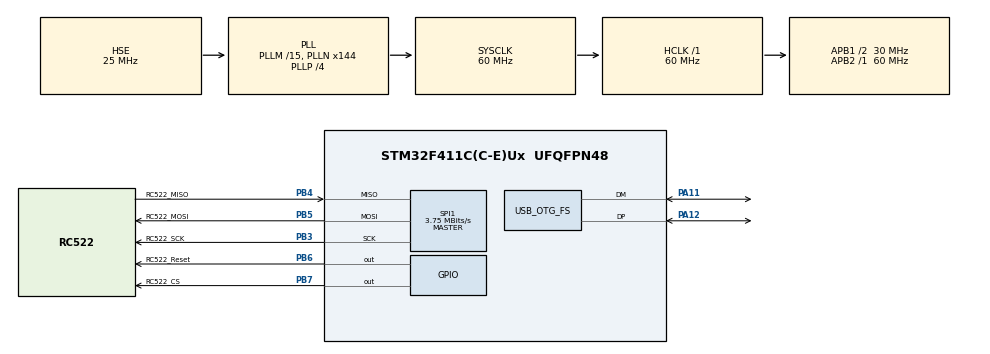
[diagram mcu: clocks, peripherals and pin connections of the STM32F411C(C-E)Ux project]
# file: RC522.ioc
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Mcu.Family=STM32F4
Mcu.Name=STM32F411C(C-E)Ux
Mcu.Package=UFQFPN48
NVIC.OTG_FS_IRQn=true\:0\:0\:false\:false\:true\:false\:true
NVIC.PriorityGroup=NVIC_PRIORITYGROUP_4
PA11.Mode=Device_Only
PA11.Signal=USB_OTG_FS_DM
PA12.Mode=Device_Only
PA12.Signal=USB_OTG_FS_DP
PA13.Mode=Serial_Wire
PA13.Signal=SYS_JTMS-SWDIO
PA14.Mode=Serial_Wire
PA14.Signal=SYS_JTCK-SWCLK
PB3.GPIO_Label=RC522_SCK
PB3.Mode=Full_Duplex_Master
PB3.Signal=SPI1_SCK
PB4.GPIO_Label=RC522_MISO
PB4.Mode=Full_Duplex_Master
PB4.Signal=SPI1_MISO
PB5.GPIO_Label=RC522_MOSI
PB5.Mode=Full_Duplex_Master
PB5.Signal=SPI1_MOSI
PB6.GPIO_Label=RC522_Reset
PB6.Signal=GPIO_Output
PB7.GPIO_Label=RC522_CS
PB7.Signal=GPIO_Output
PC14-OSC32_IN.Mode=LSE-External-Oscillator
PC14-OSC32_IN.Signal=RCC_OSC32_IN
PC15-OSC32_OUT.Mode=LSE-External-Oscillator
PC15-OSC32_OUT.Signal=RCC_OSC32_OUT
PH0\ -\ OSC_IN.Mode=HSE-External-Oscillator
PH0\ -\ OSC_IN.Signal=RCC_OSC_IN
PH1\ -\ OSC_OUT.Mode=HSE-External-Oscillator
PH1\ -\ OSC_OUT.Signal=RCC_OSC_OUT
ProjectManager.HeapSize=0x200
ProjectManager.StackSize=0x400
ProjectManager.TargetToolchain=STM32CubeIDE
RCC.48MHZClocksFreq_Value=48000000
RCC.AHBFreq_Value=60000000
RCC.APB1CLKDivider=RCC_HCLK_DIV2
RCC.APB1Freq_Value=30000000
RCC.APB1TimFreq_Value=60000000
RCC.APB2Freq_Value=60000000
RCC.APB2TimFreq_Value=60000000
RCC.CortexFreq_Value=60000000
RCC.HCLKFreq_Value=60000000
RCC.HSE_VALUE=25000000
RCC.HSI_VALUE=16000000
RCC.PLLM=15
RCC.PLLN=144
RCC.PLLP=RCC_PLLP_DIV4
RCC.PLLQ=5
RCC.SYSCLKFreq_VALUE=60000000
RCC.SYSCLKSource=RCC_SYSCLKSOURCE_PLLCLK
RCC.VCOOutputFreq_Value=240000000
SPI1.BaudRatePrescaler=SPI_BAUDRATEPRESCALER_16
SPI1.CalculateBaudRate=3.75 MBits/s
SPI1.Direction=SPI_DIRECTION_2LINES
SPI1.Mode=SPI_MODE_MASTER
SPI1.VirtualType=VM_MASTER
USB_DEVICE.CLASS_NAME_FS=CDC
USB_DEVICE.VirtualMode=Cdc
USB_DEVICE.VirtualModeFS=Cdc_FS
USB_OTG_FS.VirtualMode=Device_Only
VP_USB_DEVICE_VS_USB_DEVICE_CDC_FS.Mode=CDC_FS
board=custom

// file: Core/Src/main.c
/* USER CODE BEGIN Header */
/**
  ******************************************************************************
  * @file           : main.c
  * @brief          : Main program body
  ******************************************************************************
  * @attention
  *
  * <h2><center>&copy; Copyright (c) 2021 STMicroelectronics.
  * All rights reserved.</center></h2>
  *
  * This software component is licensed by ST under BSD 3-Clause license,
  * the "License"; You may not use this file except in compliance with the
  * License. You may obtain a copy of the License at:
  *                        opensource.org/licenses/BSD-3-Clause
  *
  ******************************************************************************
  */
/* USER CODE END Header */
#include "main.h"
#include "spi.h"
#include "usb_device.h"
#include "gpio.h"

/* USER CODE BEGIN Includes */
#include <MFRC522.h>
#include "Tools.h"
/* USER CODE END Includes */

void SystemClock_Config(void);

/* USER CODE BEGIN 0 */
extern serial Serial;
void dump_byte_array(byte *buffer, byte bufferSize) {
  for (byte i = 0; i < bufferSize; i++) {
    Serial.print((buffer[i] < 0x10 ? " 0" : " "),STR);
    Serial.print(buffer[i], HEX);
  }
}
/* USER CODE END 0 */

int main(void)
{

  /* MCU Configuration--------------------------------------------------------*/

  /* Reset of all peripherals, Initializes the Flash interface and the Systick. */
  HAL_Init();

  /* Configure the system clock */
  SystemClock_Config();

  /* Initialize all configured peripherals */
  MX_GPIO_Init();
  MX_SPI1_Init();
  MX_USB_DEVICE_Init();
  /* USER CODE BEGIN 2 */
  while(DWT_Delay_Init());
  MFRC522();
  while(serialIsConnected());
  PCD_DumpVersionToSerial();
  /* USER CODE END 2 */

  /* Infinite loop */
  while (1)
  {

    /* USER CODE BEGIN 3 */
		// Reset the loop if no new card present on the sensor/reader. This saves the entire process when idle.
		if (PICC_IsNewCardPresent()) {
			if (PICC_ReadCardSerial()) {
				PICC_DumpToSerial(&uid);
			}
		}

//	    if (PICC_IsNewCardPresent() && PICC_ReadCardSerial()) {
//	      // Show some details of the PICC (that is: the tag/card)
//	      Serial.print(F(": Card UID:"),STR);
//	      dump_byte_array(uid.uidByte, uid.size);
//	      Serial.println("",STR);
//	      Serial.print(F("PICC type: "),STR);
//	      PICC_Type piccType = PICC_GetType(uid.sak);
//	      Serial.println(PICC_GetTypeName(piccType),STR);
//
//	      // Halt PICC
//	      PICC_HaltA();
//	      // Stop encryption on PCD
//	      PCD_StopCrypto1();
//	    } //if (mfrc522[reader].PICC_IsNewC

//	   Serial.println("*****************************",STR);
//	   Serial.println("MFRC522 Digital self test",STR);
//	   Serial.println("*****************************",STR);
//	   PCD_DumpVersionToSerial();  // Show version of PCD - MFRC522 Card Reader
//	   Serial.println("-----------------------------",STR);
//	   Serial.println("Only known versions supported",STR);
//	   Serial.println("-----------------------------",STR);
//	   Serial.println("Performing test...",STR);
//	   boolean result = PCD_PerformSelfTest(); // perform the test
//	   Serial.print("-----------------------------",STR);
//	   Serial.println("Result: ",STR);
//	   if (result)
//	     Serial.println("OK",STR);
//	   else
//	     Serial.println("DEFECT or UNKNOWN",STR);
//	   Serial.println("",STR);
  }
  /* USER CODE END 3 */
}

void SystemClock_Config(void)
{
  RCC_OscInitTypeDef RCC_OscInitStruct = {0};
  RCC_ClkInitTypeDef RCC_ClkInitStruct = {0};

  /** Configure the main internal regulator output voltage
  */
  __HAL_RCC_PWR_CLK_ENABLE();
  __HAL_PWR_VOLTAGESCALING_CONFIG(PWR_REGULATOR_VOLTAGE_SCALE1);
  /** Initializes the RCC Oscillators according to the specified parameters
  * in the RCC_OscInitTypeDef structure.
  */
  RCC_OscInitStruct.OscillatorType = RCC_OSCILLATORTYPE_HSE;
  RCC_OscInitStruct.HSEState = RCC_HSE_ON;
  RCC_OscInitStruct.PLL.PLLState = RCC_PLL_ON;
  RCC_OscInitStruct.PLL.PLLSource = RCC_PLLSOURCE_HSE;
  RCC_OscInitStruct.PLL.PLLM = 15;
  RCC_OscInitStruct.PLL.PLLN = 144;
  RCC_OscInitStruct.PLL.PLLP = RCC_PLLP_DIV4;
  RCC_OscInitStruct.PLL.PLLQ = 5;
  if (HAL_RCC_OscConfig(&RCC_OscInitStruct) != HAL_OK)
  {
    Error_Handler();
  }
  /** Initializes the CPU, AHB and APB buses clocks
  */
  RCC_ClkInitStruct.ClockType = RCC_CLOCKTYPE_HCLK|RCC_CLOCKTYPE_SYSCLK
                              |RCC_CLOCKTYPE_PCLK1|RCC_CLOCKTYPE_PCLK2;
  RCC_ClkInitStruct.SYSCLKSource = RCC_SYSCLKSOURCE_PLLCLK;
  RCC_ClkInitStruct.AHBCLKDivider = RCC_SYSCLK_DIV1;
  RCC_ClkInitStruct.APB1CLKDivider = RCC_HCLK_DIV2;
  RCC_ClkInitStruct.APB2CLKDivider = RCC_HCLK_DIV1;

  if (HAL_RCC_ClockConfig(&RCC_ClkInitStruct, FLASH_LATENCY_1) != HAL_OK)
  {
    Error_Handler();
  }
}

void Error_Handler(void)
{
  __disable_irq();
  while (1)
  {
  }
}

/************************ (C) COPYRIGHT STMicroelectronics *****END OF FILE****/
